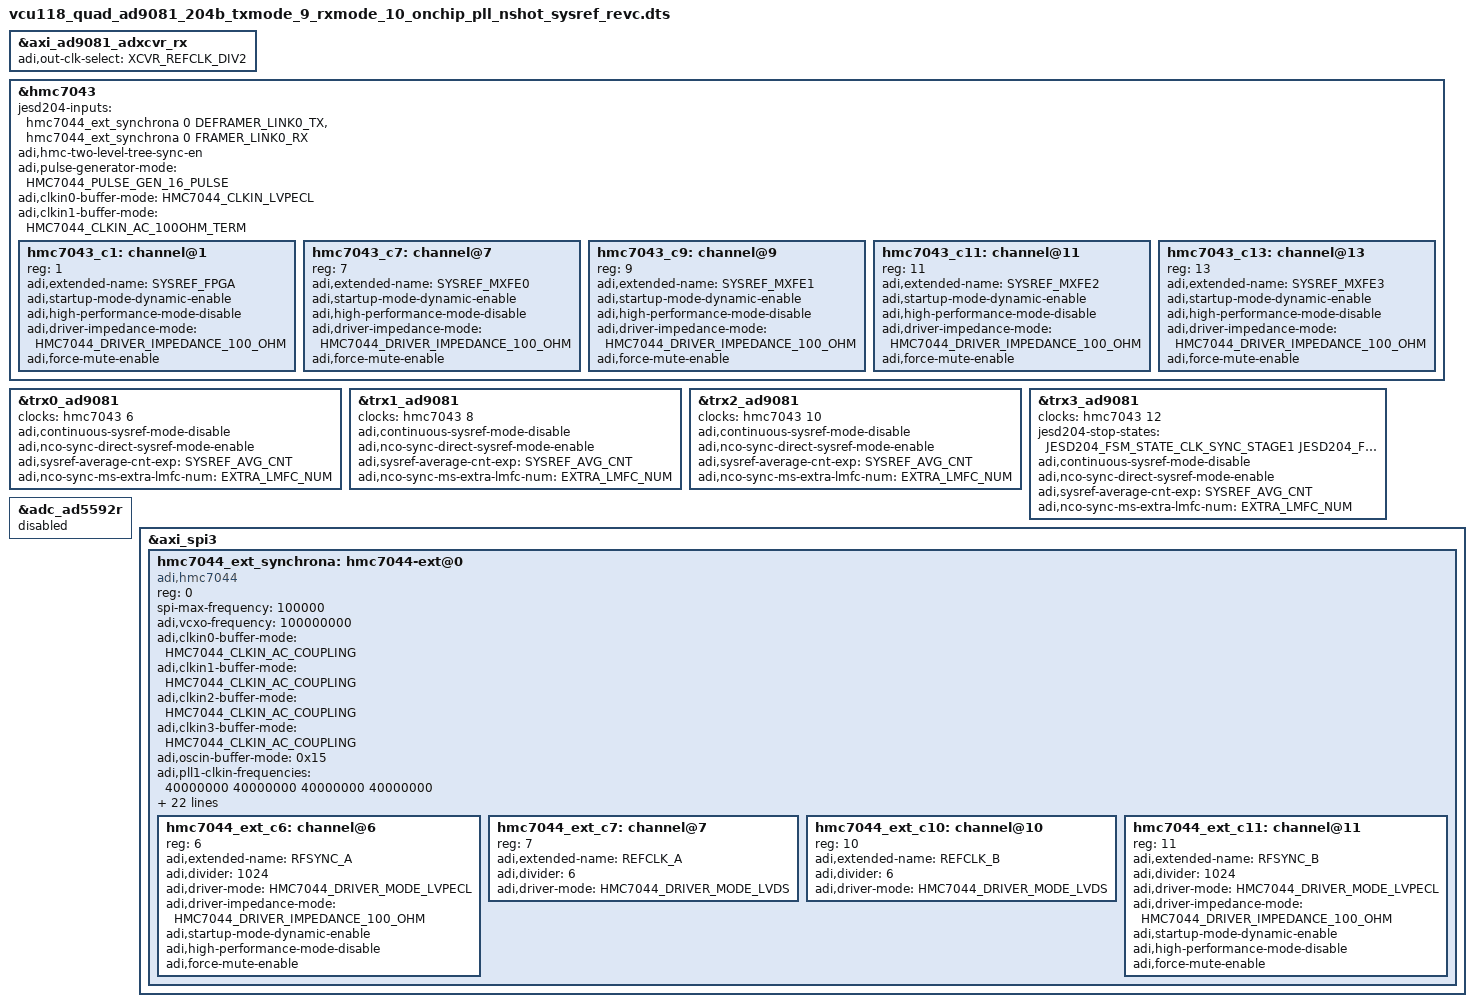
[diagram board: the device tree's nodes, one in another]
// SPDX-License-Identifier: GPL-2.0
/*
 * Analog Devices Quad-MxFE (using internal PLL)
 * https://wiki.analog.com/resources/eval/user-guides/quadmxfe
 * https://wiki.analog.com/resources/tools-software/linux-drivers/iio-mxfe/ad9081
 * https://wiki.analog.com/resources/eval/user-guides/ad_quadmxfe1_ebz/ad_quadmxfe1_ebz_hdl
 *
 * hdl_project: <ad_quadmxfe1_ebz/vcu118>
 * board_revision: <Rev.C>
 *
 * Copyright (C) 2021-2022 Analog Devices Inc.
 */

// HDL Synthesis Parameters:
// JESD_MODE=8B10B
// RX_JESD_M=8
// RX_JESD_L=4
// RX_JESD_S=1
// TX_JESD_M=8
// TX_JESD_L=4
// TX_JESD_S=1

#include "vcu118_quad_ad9081_204b_txmode_9_rxmode_10_onchip_pll_revc.dts"
#include <dt-bindings/jesd204/device-states.h>
#include <dt-bindings/jesd204/adxcvr.h>

#define SYSREF_AVG_CNT 4
#define EXTRA_LMFC_NUM 0

&axi_ad9081_adxcvr_rx{
	adi,out-clk-select = <XCVR_REFCLK_DIV2>;
};

&hmc7043 {

	jesd204-inputs = <&hmc7044_ext_synchrona 0 DEFRAMER_LINK0_TX>,
		<&hmc7044_ext_synchrona 0 FRAMER_LINK0_RX>;

	adi,hmc-two-level-tree-sync-en;

	/delete-property/ jesd204-sysref-provider;
	/delete-property/ adi,rf-reseeder-disable;

	adi,pulse-generator-mode = <HMC7044_PULSE_GEN_16_PULSE>;

	adi,clkin0-buffer-mode  = <HMC7044_CLKIN_LVPECL>; /* RFSYNC */
	adi,clkin1-buffer-mode  = <HMC7044_CLKIN_AC_100OHM_TERM>; /* CLKIN */

	hmc7043_c1: channel@1 {
		reg = <1>;
		adi,extended-name = "SYSREF_FPGA";
		adi,startup-mode-dynamic-enable;
		adi,high-performance-mode-disable;
		adi,driver-impedance-mode = <HMC7044_DRIVER_IMPEDANCE_100_OHM>;
		adi,force-mute-enable;
	};

	hmc7043_c7: channel@7 {
		reg = <7>;
		adi,extended-name = "SYSREF_MXFE0";
		adi,startup-mode-dynamic-enable;
		adi,high-performance-mode-disable;
		adi,driver-impedance-mode = <HMC7044_DRIVER_IMPEDANCE_100_OHM>;
		adi,force-mute-enable;
	};

	hmc7043_c9: channel@9 {
		reg = <9>;
		adi,extended-name = "SYSREF_MXFE1";
		adi,startup-mode-dynamic-enable;
		adi,high-performance-mode-disable;
		adi,driver-impedance-mode = <HMC7044_DRIVER_IMPEDANCE_100_OHM>;
		adi,force-mute-enable;
	};

	hmc7043_c11: channel@11 {
		reg = <11>;
		adi,extended-name = "SYSREF_MXFE2";
		adi,startup-mode-dynamic-enable;
		adi,high-performance-mode-disable;
		adi,driver-impedance-mode = <HMC7044_DRIVER_IMPEDANCE_100_OHM>;
		adi,force-mute-enable;
	};

	hmc7043_c13: channel@13 {
		reg = <13>;
		adi,extended-name = "SYSREF_MXFE3";
		adi,startup-mode-dynamic-enable;
		adi,high-performance-mode-disable;
		adi,driver-impedance-mode = <HMC7044_DRIVER_IMPEDANCE_100_OHM>;
		adi,force-mute-enable;
	};
};

&trx0_ad9081 {
	clocks = <&hmc7043 6>;
	/delete-property/ dev_clk-clock-scales;

	adi,continuous-sysref-mode-disable;
	adi,nco-sync-direct-sysref-mode-enable;
	adi,sysref-average-cnt-exp = <SYSREF_AVG_CNT>; /* 2^4=16 */
	adi,nco-sync-ms-extra-lmfc-num = <EXTRA_LMFC_NUM>;
};

&trx1_ad9081 {
	clocks = <&hmc7043 8>;
	/delete-property/ dev_clk-clock-scales;

	adi,continuous-sysref-mode-disable;
	adi,nco-sync-direct-sysref-mode-enable;
	adi,sysref-average-cnt-exp = <SYSREF_AVG_CNT>; /* 2^4=16 */
	adi,nco-sync-ms-extra-lmfc-num = <EXTRA_LMFC_NUM>;
};

&trx2_ad9081 {
	clocks = <&hmc7043 10>;
	/delete-property/ dev_clk-clock-scales;

	adi,continuous-sysref-mode-disable;
	adi,nco-sync-direct-sysref-mode-enable;
	adi,sysref-average-cnt-exp = <SYSREF_AVG_CNT>; /* 2^4=16 */
	adi,nco-sync-ms-extra-lmfc-num = <EXTRA_LMFC_NUM>;
};

&trx3_ad9081 {
	clocks = <&hmc7043 12>;
	/delete-property/ dev_clk-clock-scales;

	jesd204-stop-states = <
		JESD204_FSM_STATE_CLK_SYNC_STAGE1
		JESD204_FSM_STATE_CLK_SYNC_STAGE2
		JESD204_FSM_STATE_CLK_SYNC_STAGE3
		JESD204_FSM_STATE_OPT_SETUP_STAGE1
		JESD204_FSM_STATE_OPT_SETUP_STAGE2
		JESD204_FSM_STATE_LINK_ENABLE>;

	adi,continuous-sysref-mode-disable;
	adi,nco-sync-direct-sysref-mode-enable;
	adi,sysref-average-cnt-exp = <SYSREF_AVG_CNT>; /* 2^4=16 */
	adi,nco-sync-ms-extra-lmfc-num = <EXTRA_LMFC_NUM>;
};

/* Using AD-SYNCHRONA14-EBZ */
&adc_ad5592r {
	status = "disabled";
};

&axi_spi3 {
	hmc7044_ext_synchrona: hmc7044-ext@0 {
		#address-cells = <1>;
		#size-cells = <0>;
		#clock-cells = <1>;
		compatible = "adi,hmc7044";
		reg = <0>;
		spi-max-frequency = <100000>;

		adi,vcxo-frequency = <100000000>;

		adi,clkin0-buffer-mode = <HMC7044_CLKIN_AC_COUPLING>;
		adi,clkin1-buffer-mode = <HMC7044_CLKIN_AC_COUPLING>;
		adi,clkin2-buffer-mode = <HMC7044_CLKIN_AC_COUPLING>;
		adi,clkin3-buffer-mode = <HMC7044_CLKIN_AC_COUPLING>;
		adi,oscin-buffer-mode = <0x15>;

		adi,pll1-clkin-frequencies =
			<40000000 40000000 40000000 40000000>;

		/* CLKIN0 -> CLKIN1 -> CLKIN2 -> CLKIN3 */
		adi,pll1-ref-prio-ctrl = <0xE4>;
		adi,pll1-ref-autorevert-enable;
		adi,pll1-loop-bandwidth-hz = <200>;
		adi,pfd1-maximum-limit-frequency-hz = <3840000>;

		adi,pll2-output-frequency = <3000000000>;

		adi,pulse-generator-mode = <HMC7044_PULSE_GEN_1_PULSE>;
		adi,sync-pin-mode = <HMC7044_SYNC_PIN_DISABLED>;

		adi,gpi-controls = <0x00 0x00 0x00 0x00>;
		adi,gpo-controls = <0x1f 0x2b 0x00 0x00>;

		/* JESD204-FSM */
		jesd204-device;
		#jesd204-cells = <2>;
		jesd204-sysref-provider;
		adi,hmc-two-level-tree-sync-en;
		adi,jesd204-max-sysref-frequency-hz = <2000000>;

		clock-output-names =
			"hmc7044_e_out0", "hmc7044_e_out1",
			"hmc7044_e_out2", "hmc7044_e_out3",
			"hmc7044_e_out4", "hmc7044_e_out5",
			"hmc7044_e_out6_RFSYNC_A", "hmc7044_e_out7_REFCLK_A",
			"hmc7044_e_out8","hmc7044_e_out9",
			"hmc7044_e_out10_REFCLK_B", "hmc7044_e_out11_RFSYNC_B",
			"hmc7044_e_out12", "hmc7044_e_out13";

		hmc7044_ext_c6: channel@6 {
			reg = <6>;
			adi,extended-name = "RFSYNC_A";
			adi,divider = <1024>; /* set by the jesd204-fsm */
			adi,driver-mode = <HMC7044_DRIVER_MODE_LVPECL>;
			adi,driver-impedance-mode =
				<HMC7044_DRIVER_IMPEDANCE_100_OHM>;
			adi,startup-mode-dynamic-enable;
			adi,high-performance-mode-disable;
			adi,force-mute-enable;
		};

		hmc7044_ext_c7: channel@7 {
			reg = <7>;
			adi,extended-name = "REFCLK_A";
			adi,divider = <6>;
			adi,driver-mode = <HMC7044_DRIVER_MODE_LVDS>;
		};

		hmc7044_ext_c10: channel@10 {
			reg = <10>;
			adi,extended-name = "REFCLK_B";
			adi,divider = <6>;
			adi,driver-mode = <HMC7044_DRIVER_MODE_LVDS>;
		};

		hmc7044_ext_c11: channel@11 {
			reg = <11>;
			adi,extended-name = "RFSYNC_B";
			adi,divider = <1024>; /* set by the jesd204-fsm */
			adi,driver-mode = <HMC7044_DRIVER_MODE_LVPECL>;
			adi,driver-impedance-mode =
				<HMC7044_DRIVER_IMPEDANCE_100_OHM>;
			adi,startup-mode-dynamic-enable;
			adi,high-performance-mode-disable;
			adi,force-mute-enable;
		};
	};
};
